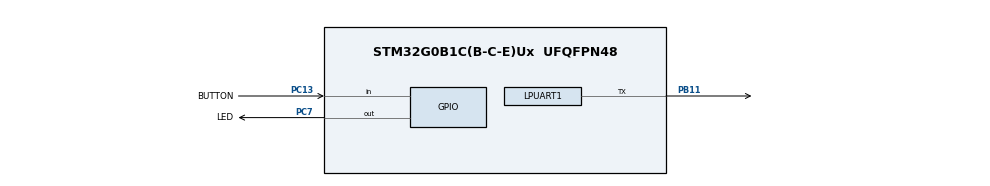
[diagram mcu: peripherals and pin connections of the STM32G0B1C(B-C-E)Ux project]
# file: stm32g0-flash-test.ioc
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FREERTOS.Tasks01=defaultTask,0,128,StartDefaultTask,Default,NULL,Dynamic,NULL,NULL;flashTask,0,128,StartFlashTask,Default,NULL,Dynamic,NULL,NULL
LPUART1.BaudRate=230400
LPUART1.Mode=UART_MODE_TX
LPUART1.WordLength=UART_WORDLENGTH_8B
Mcu.Family=STM32G0
Mcu.Name=STM32G0B1C(B-C-E)Ux
Mcu.Package=UFQFPN48
NVIC.TimeBase=TIM7_LPTIM2_IRQn
NVIC.TimeBaseIP=TIM7
PB11.Mode=Half_duplex(single_wire_mode)
PB11.Signal=LPUART1_TX
PC13.GPIO_Label=BUTTON
PC13.Signal=GPIO_Input
PC7.GPIO_Label=LED
PC7.Signal=GPIO_Output
ProjectManager.HeapSize=0x3000
ProjectManager.StackSize=0x1200
ProjectManager.TargetToolchain=Makefile
RCC.ADCFreq_Value=64000000
RCC.AHBFreq_Value=64000000
RCC.CortexFreq_Value=64000000
RCC.EXTERNAL_CLOCK_VALUE=48000
RCC.HCLKFreq_Value=64000000
RCC.HSE_VALUE=8000000
RCC.HSI48_VALUE=48000000
RCC.HSI_VALUE=16000000
RCC.LSE_VALUE=32768
RCC.SYSCLKFreq_VALUE=64000000
RCC.SYSCLKSource=RCC_SYSCLKSOURCE_PLLCLK
RCC.USBFreq_Value=48000000
RCC.VCOOutputFreq_Value=128000000
VP_FREERTOS_VS_CMSIS_V1.Mode=CMSIS_V1
VP_SYS_VS_DBSignals.Mode=DisableDeadBatterySignals
VP_SYS_VS_tim7.Mode=TIM7
board=custom

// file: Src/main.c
/* USER CODE BEGIN Header */
/**
  ******************************************************************************
  * @file           : main.c
  * @brief          : Main program body
  ******************************************************************************
  * @attention
  *
  * Copyright (c) 2023 STMicroelectronics.
  * All rights reserved.
  *
  * This software is licensed under terms that can be found in the LICENSE file
  * in the root directory of this software component.
  * If no LICENSE file comes with this software, it is provided AS-IS.
  *
  ******************************************************************************
  */
/* USER CODE END Header */
#include "main.h"
#include "cmsis_os.h"

/* USER CODE BEGIN Includes */
#include <stdbool.h>
#include <stdint.h>
#include <stdio.h>
#include "flash.h"
/* USER CODE END Includes */

osThreadId defaultTaskHandle;
osThreadId flashTaskHandle;

void SystemClock_Config(void);
static void MX_GPIO_Init(void);
static void MX_LPUART1_UART_Init(void);
void StartDefaultTask(void const * argument);
void StartFlashTask(void const * argument);

/* USER CODE BEGIN 0 */
void DEBUG_Print(char *buffer, int buffer_length)
{
  uint32_t index = 0;

  if (buffer[buffer_length - 1] == 0)
  {
    buffer_length -= 1;
  }

  for (index = 0; index < buffer_length; index++)
  {
    while (!LL_LPUART_IsActiveFlag_TXE(LPUART1))
    {
    }

    LL_LPUART_TransmitData8(LPUART1, buffer[index]);
  }

  while (!LL_LPUART_IsActiveFlag_TC(LPUART1))
  {
  }
}
/* USER CODE END 0 */

int main(void)
{

  /* MCU Configuration--------------------------------------------------------*/

  /* Reset of all peripherals, Initializes the Flash interface and the Systick. */
  HAL_Init();

  /* Configure the system clock */
  SystemClock_Config();

  /* Initialize all configured peripherals */
  MX_GPIO_Init();
  MX_LPUART1_UART_Init();

  /* Create the thread(s) */
  /* definition and creation of defaultTask */
  osThreadDef(defaultTask, StartDefaultTask, osPriorityNormal, 0, 128);
  defaultTaskHandle = osThreadCreate(osThread(defaultTask), NULL);

  /* definition and creation of flashTask */
  osThreadDef(flashTask, StartFlashTask, osPriorityNormal, 0, 128);
  flashTaskHandle = osThreadCreate(osThread(flashTask), NULL);

  /* Start scheduler */
  osKernelStart();

  /* We should never get here as control is now taken by the scheduler */
  /* Infinite loop */
  while (1)
  {
  }
}

void SystemClock_Config(void)
{
  LL_FLASH_SetLatency(LL_FLASH_LATENCY_2);
  while(LL_FLASH_GetLatency() != LL_FLASH_LATENCY_2)
  {
  }

  /* HSI configuration and activation */
  LL_RCC_HSI_Enable();
  while(LL_RCC_HSI_IsReady() != 1)
  {
  }

  /* Main PLL configuration and activation */
  LL_RCC_PLL_ConfigDomain_SYS(LL_RCC_PLLSOURCE_HSI, LL_RCC_PLLM_DIV_1, 8, LL_RCC_PLLR_DIV_2);
  LL_RCC_PLL_Enable();
  LL_RCC_PLL_EnableDomain_SYS();
  while(LL_RCC_PLL_IsReady() != 1)
  {
  }

  /* Set AHB prescaler*/
  LL_RCC_SetAHBPrescaler(LL_RCC_SYSCLK_DIV_1);

  /* Sysclk activation on the main PLL */
  LL_RCC_SetSysClkSource(LL_RCC_SYS_CLKSOURCE_PLL);
  while(LL_RCC_GetSysClkSource() != LL_RCC_SYS_CLKSOURCE_STATUS_PLL)
  {
  }

  /* Set APB1 prescaler*/
  LL_RCC_SetAPB1Prescaler(LL_RCC_APB1_DIV_1);
  /* Update CMSIS variable (which can be updated also through SystemCoreClockUpdate function) */
  LL_SetSystemCoreClock(64000000);

   /* Update the time base */
  if (HAL_InitTick (TICK_INT_PRIORITY) != HAL_OK)
  {
    Error_Handler();
  }
}

static void MX_LPUART1_UART_Init(void)
{

  LL_LPUART_InitTypeDef LPUART_InitStruct = {0};

  LL_GPIO_InitTypeDef GPIO_InitStruct = {0};

  LL_RCC_SetLPUARTClockSource(LL_RCC_LPUART1_CLKSOURCE_PCLK1);

  /* Peripheral clock enable */
  LL_APB1_GRP1_EnableClock(LL_APB1_GRP1_PERIPH_LPUART1);

  LL_IOP_GRP1_EnableClock(LL_IOP_GRP1_PERIPH_GPIOB);
  /**LPUART1 GPIO Configuration
  PB11   ------> LPUART1_TX
  */
  GPIO_InitStruct.Pin = LL_GPIO_PIN_11;
  GPIO_InitStruct.Mode = LL_GPIO_MODE_ALTERNATE;
  GPIO_InitStruct.Speed = LL_GPIO_SPEED_FREQ_LOW;
  GPIO_InitStruct.OutputType = LL_GPIO_OUTPUT_OPENDRAIN;
  GPIO_InitStruct.Pull = LL_GPIO_PULL_UP;
  GPIO_InitStruct.Alternate = LL_GPIO_AF_1;
  LL_GPIO_Init(GPIOB, &GPIO_InitStruct);

  LPUART_InitStruct.PrescalerValue = LL_LPUART_PRESCALER_DIV1;
  LPUART_InitStruct.BaudRate = 230400;
  LPUART_InitStruct.DataWidth = LL_LPUART_DATAWIDTH_8B;
  LPUART_InitStruct.StopBits = LL_LPUART_STOPBITS_1;
  LPUART_InitStruct.Parity = LL_LPUART_PARITY_NONE;
  LPUART_InitStruct.TransferDirection = LL_LPUART_DIRECTION_TX;
  LL_LPUART_Init(LPUART1, &LPUART_InitStruct);
  LL_LPUART_SetTXFIFOThreshold(LPUART1, LL_LPUART_FIFOTHRESHOLD_1_8);
  LL_LPUART_SetRXFIFOThreshold(LPUART1, LL_LPUART_FIFOTHRESHOLD_1_8);
  LL_LPUART_EnableHalfDuplex(LPUART1);
  LL_LPUART_DisableFIFO(LPUART1);

  LL_LPUART_Enable(LPUART1);

  /* Polling LPUART1 initialisation */
  while(!(LL_LPUART_IsActiveFlag_TEACK(LPUART1)))
  {
  }

}

static void MX_GPIO_Init(void)
{
  LL_GPIO_InitTypeDef GPIO_InitStruct = {0};

  /* GPIO Ports Clock Enable */
  LL_IOP_GRP1_EnableClock(LL_IOP_GRP1_PERIPH_GPIOA);
  LL_IOP_GRP1_EnableClock(LL_IOP_GRP1_PERIPH_GPIOB);
  LL_IOP_GRP1_EnableClock(LL_IOP_GRP1_PERIPH_GPIOC);

  /**/
  LL_GPIO_ResetOutputPin(LED_GPIO_Port, LED_Pin);

  /**/
  GPIO_InitStruct.Pin = BUTTON_Pin;
  GPIO_InitStruct.Mode = LL_GPIO_MODE_INPUT;
  GPIO_InitStruct.Pull = LL_GPIO_PULL_NO;
  LL_GPIO_Init(BUTTON_GPIO_Port, &GPIO_InitStruct);

  /**/
  GPIO_InitStruct.Pin = LED_Pin;
  GPIO_InitStruct.Mode = LL_GPIO_MODE_OUTPUT;
  GPIO_InitStruct.Speed = LL_GPIO_SPEED_FREQ_LOW;
  GPIO_InitStruct.OutputType = LL_GPIO_OUTPUT_PUSHPULL;
  GPIO_InitStruct.Pull = LL_GPIO_PULL_NO;
  LL_GPIO_Init(LED_GPIO_Port, &GPIO_InitStruct);

}

void StartDefaultTask(void const * argument)
{
  /* USER CODE BEGIN 5 */
  /* Infinite loop */
  for(;;)
  {
  	LL_GPIO_TogglePin(LED_GPIO_Port, LED_Pin);
    osDelay(1000);
  }
  /* USER CODE END 5 */
}

void StartFlashTask(void const * argument)
{
  /* USER CODE BEGIN StartFlashTask */
  bool buttonPressed = false;
  uint32_t address = FLASH_BASE + (65 * FLASH_PAGE_SIZE); // Page 65
  uint8_t buffer[256] = {0};

  /* Infinite loop */
  for(;;)
  {
  	if (!LL_GPIO_IsInputPinSet(BUTTON_GPIO_Port, BUTTON_Pin) && buttonPressed == false)
	{
		buttonPressed = true;
		uint8_t data[16] = "Hello, World!!!!";
		uint32_t status = flash_write(address, data, 16);
		flash_read(address, buffer, 16);
		uint32_t length = sprintf((char *)buffer + 15, " Status: %lu\r\n", status);
		DEBUG_Print((char *)buffer, length + 15);

		if (status != 0)
		{
			Error_Handler();
		}
	}

  	if (LL_GPIO_IsInputPinSet(BUTTON_GPIO_Port, BUTTON_Pin) && buttonPressed == true)
	{
		buttonPressed = false;
	}

    osDelay(1);
  }
  /* USER CODE END StartFlashTask */
}

void HAL_TIM_PeriodElapsedCallback(TIM_HandleTypeDef *htim)
{
  if (htim->Instance == TIM7) {
    HAL_IncTick();
  }
}

void Error_Handler(void)
{
  /* USER CODE BEGIN Error_Handler_Debug */
  /* User can add his own implementation to report the HAL error return state */
  vTaskSuspendAll();

  while (1)
  {
  	  LL_GPIO_TogglePin(LED_GPIO_Port, LED_Pin);
  	  HAL_Delay(100);
  }
  /* USER CODE END Error_Handler_Debug */
}
